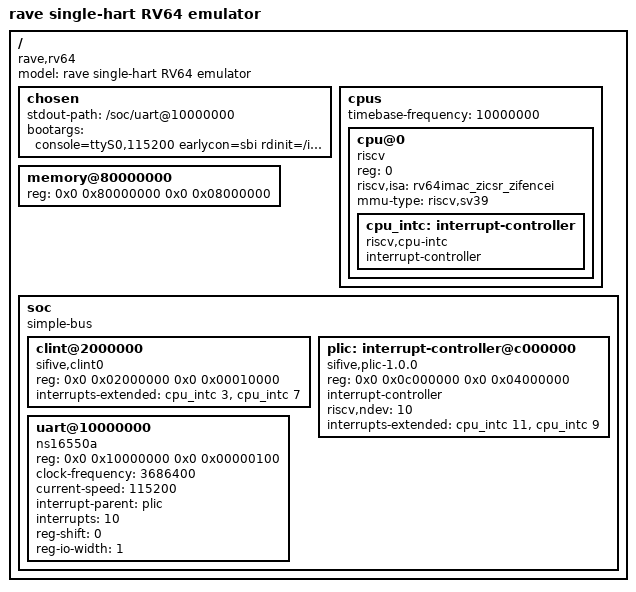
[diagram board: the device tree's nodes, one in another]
/dts-v1/;

/ {
    compatible = "rave,rv64";
    model = "rave single-hart RV64 emulator";
    #address-cells = <2>;
    #size-cells = <2>;

    chosen {
        stdout-path = "/soc/uart@10000000";
        bootargs = "console=ttyS0,115200 earlycon=sbi rdinit=/init";
    };

    cpus {
        #address-cells = <1>;
        #size-cells = <0>;
        timebase-frequency = <10000000>;

        cpu@0 {
            device_type = "cpu";
            reg = <0>;
            status = "okay";
            compatible = "riscv";
            riscv,isa = "rv64imac_zicsr_zifencei";
            mmu-type = "riscv,sv39";

            cpu_intc: interrupt-controller {
                #interrupt-cells = <1>;
                interrupt-controller;
                compatible = "riscv,cpu-intc";
            };
        };
    };

    memory@80000000 {
        device_type = "memory";
        reg = <0x0 0x80000000 0x0 0x08000000>;
    };

    soc {
        compatible = "simple-bus";
        #address-cells = <2>;
        #size-cells = <2>;
        ranges;

        clint@2000000 {
            compatible = "sifive,clint0", "riscv,clint0";
            reg = <0x0 0x02000000 0x0 0x00010000>;
            interrupts-extended = <&cpu_intc 3 &cpu_intc 7>;
        };

        plic: interrupt-controller@c000000 {
            compatible = "sifive,plic-1.0.0", "riscv,plic0";
            reg = <0x0 0x0c000000 0x0 0x04000000>;
            #interrupt-cells = <1>;
            interrupt-controller;
            riscv,ndev = <10>;
            interrupts-extended = <&cpu_intc 11 &cpu_intc 9>;
        };

        uart@10000000 {
            compatible = "ns16550a";
            reg = <0x0 0x10000000 0x0 0x00000100>;
            clock-frequency = <3686400>;
            current-speed = <115200>;
            interrupt-parent = <&plic>;
            interrupts = <10>;
            reg-shift = <0>;
            reg-io-width = <1>;
        };
    };
};
